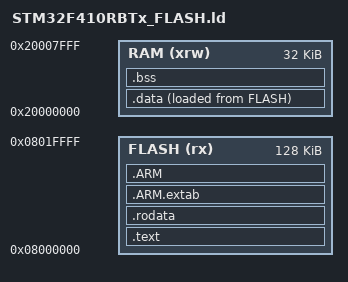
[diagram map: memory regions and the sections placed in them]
/* Entry Point */
ENTRY(main)

/* Specify the memory areas */
MEMORY
{
  FLASH (rx)      : ORIGIN = 0x08000000, LENGTH = 128K
  RAM (xrw)      : ORIGIN = 0x20000000, LENGTH = 32K
}

/* Define output sections */
SECTIONS
{
  /* The program code and other data goes into FLASH */
  .text :
  {
    . = ALIGN(4);
    *(.text)           /* .text sections (code) */
    *(.text*)          /* .text* sections (code) */
    *(.glue_7)         /* glue arm to thumb code */
    *(.glue_7t)        /* glue thumb to arm code */
    *(.eh_frame)

    KEEP (*(.init))
    KEEP (*(.fini))

    . = ALIGN(4);
    _etext = .;        /* define a global symbols at end of code */
  } >FLASH

  /* Constant data goes into FLASH */
  .rodata :
  {
    . = ALIGN(4);
    *(.rodata)         /* .rodata sections (constants, strings, etc.) */
    *(.rodata*)        /* .rodata* sections (constants, strings, etc.) */
    . = ALIGN(4);
  } >FLASH

  .ARM.extab   : { *(.ARM.extab* .gnu.linkonce.armextab.*) } >FLASH
  .ARM : {
    __exidx_start = .;
    *(.ARM.exidx*)
    __exidx_end = .;
  } >FLASH

  /* Initialized data sections goes into RAM, load LMA copy after code */
  .data : 
  {
    . = ALIGN(4);
    *(.data)           /* .data sections */
    *(.data*)          /* .data* sections */

    . = ALIGN(4);
  } >RAM AT> FLASH
  
  /* Uninitialized data section */
  .bss : ALIGN(4)
  {
    *(.bss*)
    *(COMMON)

    . = ALIGN(4);
  } >RAM

  /* Remove information from the standard libraries */
  /DISCARD/ :
  {
    libc.a ( * )
    libm.a ( * )
    libgcc.a ( * )
  }

  .ARM.attributes 0 : { *(.ARM.attributes) }  
}


